# XMC4700 register map
Vendor: Infineon; File version: 1.0.3 (Reference Manual v1.0)
CPU: CM4 r2p0, little endian, MPU, FPU, 6 interrupt priority bits
Registers are 32-bit, read-write, reset 0x0 unless marked. A register's access mark holds for its fields unless they carry their own. Offsets are from the block's base; [hi:lo] are bit positions; {n}, {i} and the like mark numbered series.

## USB0_CH0 — Universal Serial Bus
Base 0x50040500
Same registers: USB0_CH{n} {0x50040500+0x20*n} (n=1..13)
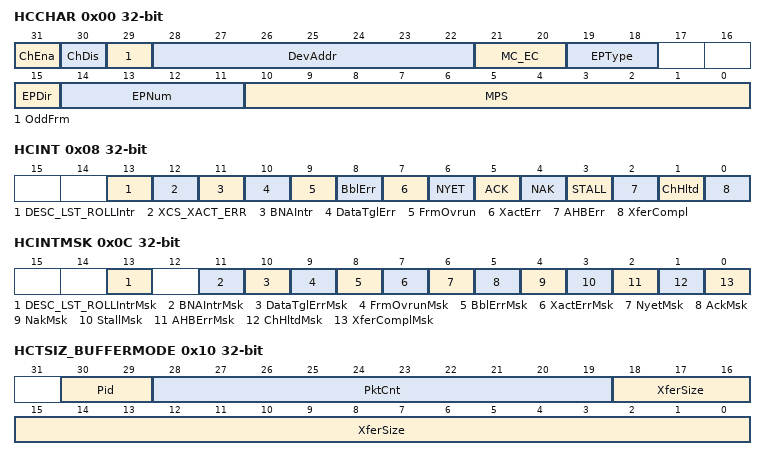
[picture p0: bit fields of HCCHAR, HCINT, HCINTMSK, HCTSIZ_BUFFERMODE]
0x00 HCCHAR — Host Channel Characteristics Register
  [31] ChEna — Channel Enable
    0=Scatter/Gather mode enabled: Indicates that the descriptor structure is not yet ready. Scatter/Gather mode disabled: Channel disabled; 1=Scatter/Gather mode enabled: Indicates that the descriptor structure and data buffer with data is setup and this channel can access the descriptor. Scatter/Gather mode disabled: Channel enabled
  [30] ChDis — Channel Disable
  [29] OddFrm — Odd Frame
    0=Even frame; 1=Odd frame
  [28:22] DevAddr — Device Address
  [21:20] MC_EC — Multi Count / Error Count
    1=1 transaction; 2=2 transactions to be issued for this endpoint per frame; 3=3 transactions to be issued for this endpoint per frame
  [19:18] EPType — Endpoint Type
    0=Control; 1=Isochronous; 2=Bulk; 3=Interrupt
  [15] EPDir — Endpoint Direction
    0=OUT; 1=IN
  [14:11] EPNum — Endpoint Number
  [10:0] MPS — Maximum Packet Size
0x08 HCINT — Host Channel Interrupt Register
  [13] DESC_LST_ROLLIntr — Descriptor rollover interrupt
  [12] XCS_XACT_ERR — Excessive Transaction Error
  [11] BNAIntr — BNA (Buffer Not Available) Interrupt
  [10] DataTglErr — Data Toggle Error
  [9] FrmOvrun — Frame Overrun
  [8] BblErr — Babble Error
  [7] XactErr — Transaction Error
  [6] NYET — NYET Response Received Interrupt
  [5] ACK — ACK Response Received/Transmitted Interrupt
  [4] NAK — NAK Response Received Interrupt
  [3] STALL — STALL Response Received Interrupt
  [2] AHBErr — AHB Error
  [1] ChHltd — Channel Halted
  [0] XferCompl — Transfer Completed
0x0C HCINTMSK — Host Channel Interrupt Mask Register
  [13] DESC_LST_ROLLIntrMsk — Descriptor rollover interrupt Mask register
  [11] BNAIntrMsk — BNA (Buffer Not Available) Interrupt mask register
  [10] DataTglErrMsk — Data Toggle Error Mask
  [9] FrmOvrunMsk — Frame Overrun Mask
  [8] BblErrMsk — Babble Error Mask
  [7] XactErrMsk — Transaction Error Mask
  [6] NyetMsk — NYET Response Received Interrupt Mask
  [5] AckMsk — ACK Response Received/Transmitted Interrupt Mask
  [4] NakMsk — NAK Response Received Interrupt Mask
  [3] StallMsk — STALL Response Received Interrupt Mask
  [2] AHBErrMsk — AHB Error Mask
  [1] ChHltdMsk — Channel Halted Mask
  [0] XferComplMsk — Transfer Completed Mask
0x10 HCTSIZ_BUFFERMODE — Host Channel Transfer Size Register [BUFFERMODE]
  [30:29] Pid
    0=DATA0; 1=DATA2; 2=DATA1; 3=MDATA (non-control)/SETUP (control)
  [28:19] PktCnt — Packet Count
  [18:0] XferSize — Transfer Size
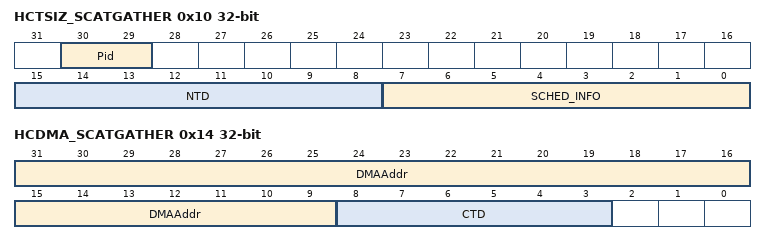
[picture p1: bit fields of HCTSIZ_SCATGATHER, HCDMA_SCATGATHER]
0x10 HCTSIZ_SCATGATHER (alternate view of HCTSIZ_BUFFERMODE) — Host Channel Transfer Size Register [SCATGATHER]
  [30:29] Pid
    0=DATA0; 1=DATA2; 2=DATA1; 3=MDATA (non-control)
  [15:8] NTD — Number of Transfer Descriptors: 0=1 descriptor, 63=64 descriptors, 1=2 descriptors, 3=4 descriptors, 7=8 descriptors, 15=16 descriptors, 31=32 descriptors, 63=64 descriptors,
  [7:0] SCHED_INFO — Schedule information
0x14 HCDMA_BUFFERMODE read-has-side-effects — Host Channel DMA Address Register [BUFFERMODE]
  [31:0] DMAAddr — DMA Address
0x14 HCDMA_SCATGATHER read-has-side-effects (alternate view of HCDMA_BUFFERMODE) — Host Channel DMA Address Register [SCATGATHER]
  [31:9] DMAAddr — DMA Address
  [8:3] CTD — Current Transfer Desc:
    0=1 descriptor; 63=64 descriptors
0x1C HCDMAB ro — Host Channel DMA Buffer Address Register
  [31:0] Buffer_Address

## USIC0 — Universal Serial Interface Controller 0
Base 0x40030008
Same registers: USIC1 0x48020008, USIC2 0x48024008
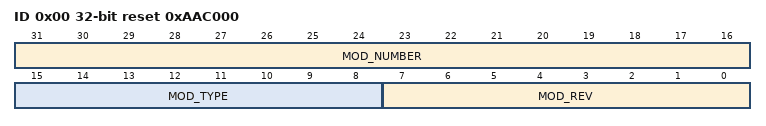
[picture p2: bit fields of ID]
0x00 ID ro reset 0xAAC000 (reset mask 0xFFFFFF00) — Module Identification Register
  [31:16] MOD_NUMBER — Module Number Value
  [15:8] MOD_TYPE — Module Type
  [7:0] MOD_REV — Module Revision Number

## Notices in the file
Copyright (c) 2016, Infineon Technologies AG
All rights reserved.
Redistribution and use in source and binary forms, with or without modification,are permitted provided that the
following conditions are met:
Redistributions of source code must retain the above copyright notice, this list of conditions and the following
disclaimer.
Redistributions in binary form must reproduce the above copyright notice, this list of conditions and the following
disclaimer in the documentation and/or other materials provided with the distribution.
Neither the name of the copyright holders nor the names of its contributors may be used to endorse or promote
products derived from this software without specific prior written permission.
THIS SOFTWARE IS PROVIDED BY THE COPYRIGHT HOLDERS AND CONTRIBUTORS "AS IS" AND ANY EXPRESS OR IMPLIED WARRANTIES,
INCLUDING, BUT NOT LIMITED TO, THE IMPLIED WARRANTIES OF MERCHANTABILITY AND FITNESS FOR A PARTICULAR PURPOSE ARE
DISCLAIMED. IN NO EVENT SHALL THE COPYRIGHT HOLDER OR CONTRIBUTORS BE LIABLE  FOR ANY DIRECT, INDIRECT, INCIDENTAL,
SPECIAL, EXEMPLARY, OR CONSEQUENTIAL DAMAGES (INCLUDING, BUT NOT LIMITED TO, PROCUREMENT OF SUBSTITUTE GOODS OR
SERVICES; LOSS OF USE, DATA, OR PROFITS; OR BUSINESS INTERRUPTION) HOWEVER CAUSED AND ON ANY THEORY OF LIABILITY,
WHETHER IN CONTRACT, STRICT LIABILITY,OR TORT (INCLUDING NEGLIGENCE OR OTHERWISE) ARISING IN ANY WAY OUT OF THE USE
OF THIS SOFTWARE, EVEN IF ADVISED OF THE POSSIBILITY OF SUCH DAMAGE.
